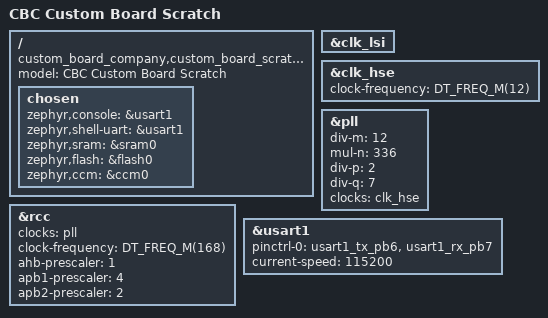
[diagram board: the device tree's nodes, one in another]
/*
 * Copyright (c) 2017, Erwin Rol <erwin@erwinrol.com>
 *
 * SPDX-License-Identifier: Apache-2.0
 */

/dts-v1/;
#include <st/f4/stm32f407Xg.dtsi>
#include <st/f4/stm32f407z(e-g)tx-pinctrl.dtsi>

/ {
	model = "CBC Custom Board Scratch";
	compatible = "custom_board_company,custom_board_scratch";

	chosen {
		zephyr,console = &usart1;
		zephyr,shell-uart = &usart1;
		zephyr,sram = &sram0;
		zephyr,flash = &flash0;
		zephyr,ccm = &ccm0;
	};
};

&clk_lsi {
	status = "okay";
};

&clk_hse {
	clock-frequency = <DT_FREQ_M(12)>;
	status = "okay";
};

&pll {
	div-m = <12>;
	mul-n = <336>;
	div-p = <2>;
	div-q = <7>;
	clocks = <&clk_hse>;
	status = "okay";
};

&rcc {
	clocks = <&pll>;
	clock-frequency = <DT_FREQ_M(168)>;
	ahb-prescaler = <1>;
	apb1-prescaler = <4>;
	apb2-prescaler = <2>;
};

&usart1 {
	pinctrl-0 = <&usart1_tx_pb6 &usart1_rx_pb7>;
	pinctrl-names = "default";
	current-speed = <115200>;
	status = "okay";
};
